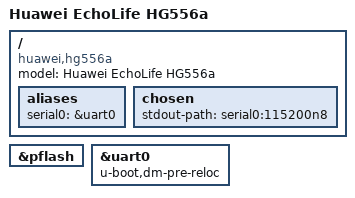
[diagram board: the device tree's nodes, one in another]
/*
 * Copyright (C) 2017 Álvaro Fernández Rojas <noltari@gmail.com>
 *
 * SPDX-License-Identifier:	GPL-2.0+
 */

/dts-v1/;

#include "brcm,bcm6358.dtsi"

/ {
	model = "Huawei EchoLife HG556a";
	compatible = "huawei,hg556a", "brcm,bcm6358";

	aliases {
		serial0 = &uart0;
	};

	chosen {
		stdout-path = "serial0:115200n8";
	};
};

&pflash {
	status = "okay";
};

&uart0 {
	u-boot,dm-pre-reloc;
	status = "okay";
};
